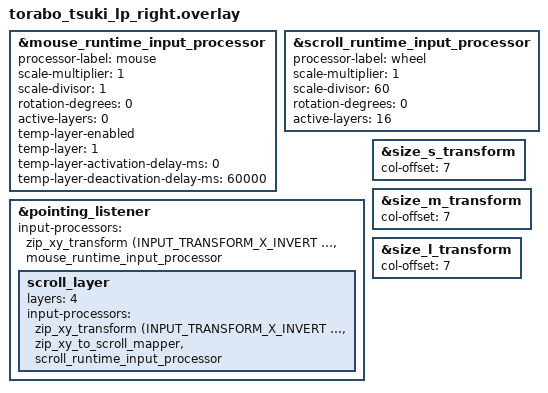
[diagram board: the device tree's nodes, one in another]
#define TORABO_TSUKI_LP_RIGHT 1

#include "torabo_tsuki_lp.dtsi"
#include <input/processors.dtsi>
#include <dt-bindings/zmk/input_transform.h>
#include <input/processors/runtime-input-processor.dtsi>

&mouse_runtime_input_processor {
    processor-label = "mouse";
    scale-multiplier = <1>;
    scale-divisor = <1>;
    rotation-degrees = <0>;
    active-layers = <0>;
    temp-layer-enabled;
    temp-layer = <1>;
    temp-layer-activation-delay-ms = <0>;
    temp-layer-deactivation-delay-ms = <60000>;
};

&scroll_runtime_input_processor {
    processor-label = "wheel";
    scale-multiplier = <1>;
    scale-divisor = <60>;
    rotation-degrees = <0>;
    active-layers = <16>;
};

&pointing_listener {
    input-processors = <&zip_xy_transform (INPUT_TRANSFORM_X_INVERT | INPUT_TRANSFORM_Y_INVERT) &mouse_runtime_input_processor>;

    scroll_layer {
        layers = <4>;
        input-processors = <&zip_xy_transform (INPUT_TRANSFORM_X_INVERT | INPUT_TRANSFORM_Y_INVERT) &zip_xy_to_scroll_mapper &scroll_runtime_input_processor>;
    };
};

&size_s_transform {
    col-offset = <7>;
};

&size_m_transform {
    col-offset = <7>;
};

&size_l_transform {
    col-offset = <7>;
};
